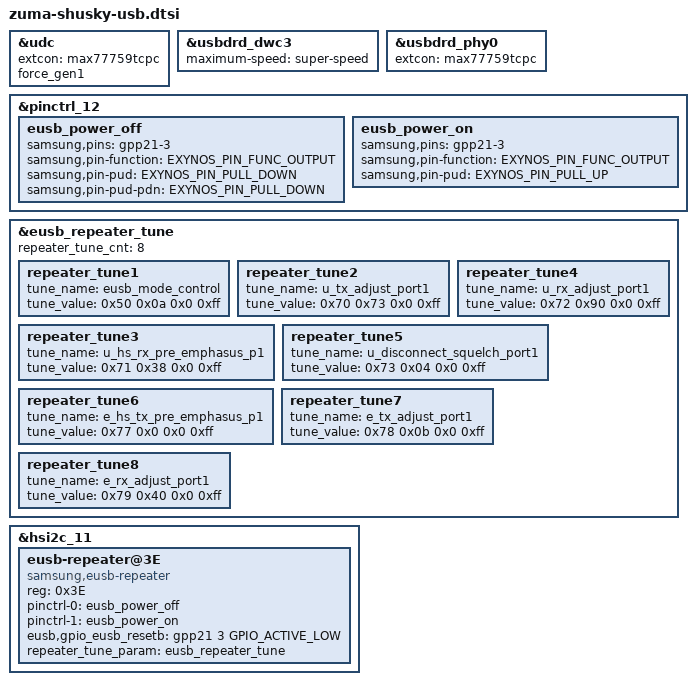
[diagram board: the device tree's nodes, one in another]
// SPDX-License-Identifier: GPL-2.0-only
/*
 * USB device tree source code for Zuma SoC
 *
 * Copyright 2022 Google LLC.
 */

&udc {
	extcon = <&max77759tcpc>;
	force_gen1;
};

&usbdrd_dwc3 {
	maximum-speed = "super-speed";
};

&usbdrd_phy0 {
	extcon = <&max77759tcpc>;
};

&pinctrl_12 {
	eusb_power_off: eusb_power_off {
		samsung,pins = "gpp21-3";
		samsung,pin-function = <EXYNOS_PIN_FUNC_OUTPUT>;
		samsung,pin-pud = <EXYNOS_PIN_PULL_DOWN>;
		samsung,pin-pud-pdn = <EXYNOS_PIN_PULL_DOWN>;
	};

	eusb_power_on: eusb_power_on {
		samsung,pins = "gpp21-3";
		samsung,pin-function = <EXYNOS_PIN_FUNC_OUTPUT>;
		samsung,pin-pud = <EXYNOS_PIN_PULL_UP>;
	};
};

&eusb_repeater_tune {
	status = "okay";
	repeater_tune_cnt = <8>;
	/* 0xffffffff means using default value */
	/* tune value - reg value shift mask*/
	repeater_tune1 {
		tune_name = "eusb_mode_control";
		tune_value = <0x50 0x0a 0x0 0xff>;
	};

	repeater_tune2 {
		tune_name = "u_tx_adjust_port1";
		tune_value = <0x70 0x73 0x0 0xff>;
	};

	repeater_tune3 {
		tune_name = "u_hs_rx_pre_emphasus_p1";
		tune_value = <0x71 0x38 0x0 0xff>;
	};

	repeater_tune4 {
		tune_name = "u_rx_adjust_port1";
		tune_value = <0x72 0x90 0x0 0xff>;
	};

	repeater_tune5 {
		tune_name = "u_disconnect_squelch_port1";
		tune_value = <0x73 0x04 0x0 0xff>;
	};

	repeater_tune6 {
		tune_name = "e_hs_tx_pre_emphasus_p1";
		tune_value = <0x77 0x0 0x0 0xff>;
	};

	repeater_tune7 {
		tune_name = "e_tx_adjust_port1";
		tune_value = <0x78 0x0b 0x0 0xff>;
	};

	repeater_tune8 {
		tune_name = "e_rx_adjust_port1";
		tune_value = <0x79 0x40 0x0 0xff>;
	};
};

&hsi2c_11 {
       #address-cells = <1>;
       #size-cells = <0>;
       status = "okay";
       eusb-repeater@3E {
		compatible = "samsung,eusb-repeater";
		reg = <0x3E>;
		status = "okay";
		pinctrl-names = "power_off", "power_on";
		pinctrl-0 = <&eusb_power_off>;
		pinctrl-1 = <&eusb_power_on>;
		eusb,gpio_eusb_resetb = <&gpp21 3 GPIO_ACTIVE_LOW>;
		repeater_tune_param = <&eusb_repeater_tune>;
       };
};
